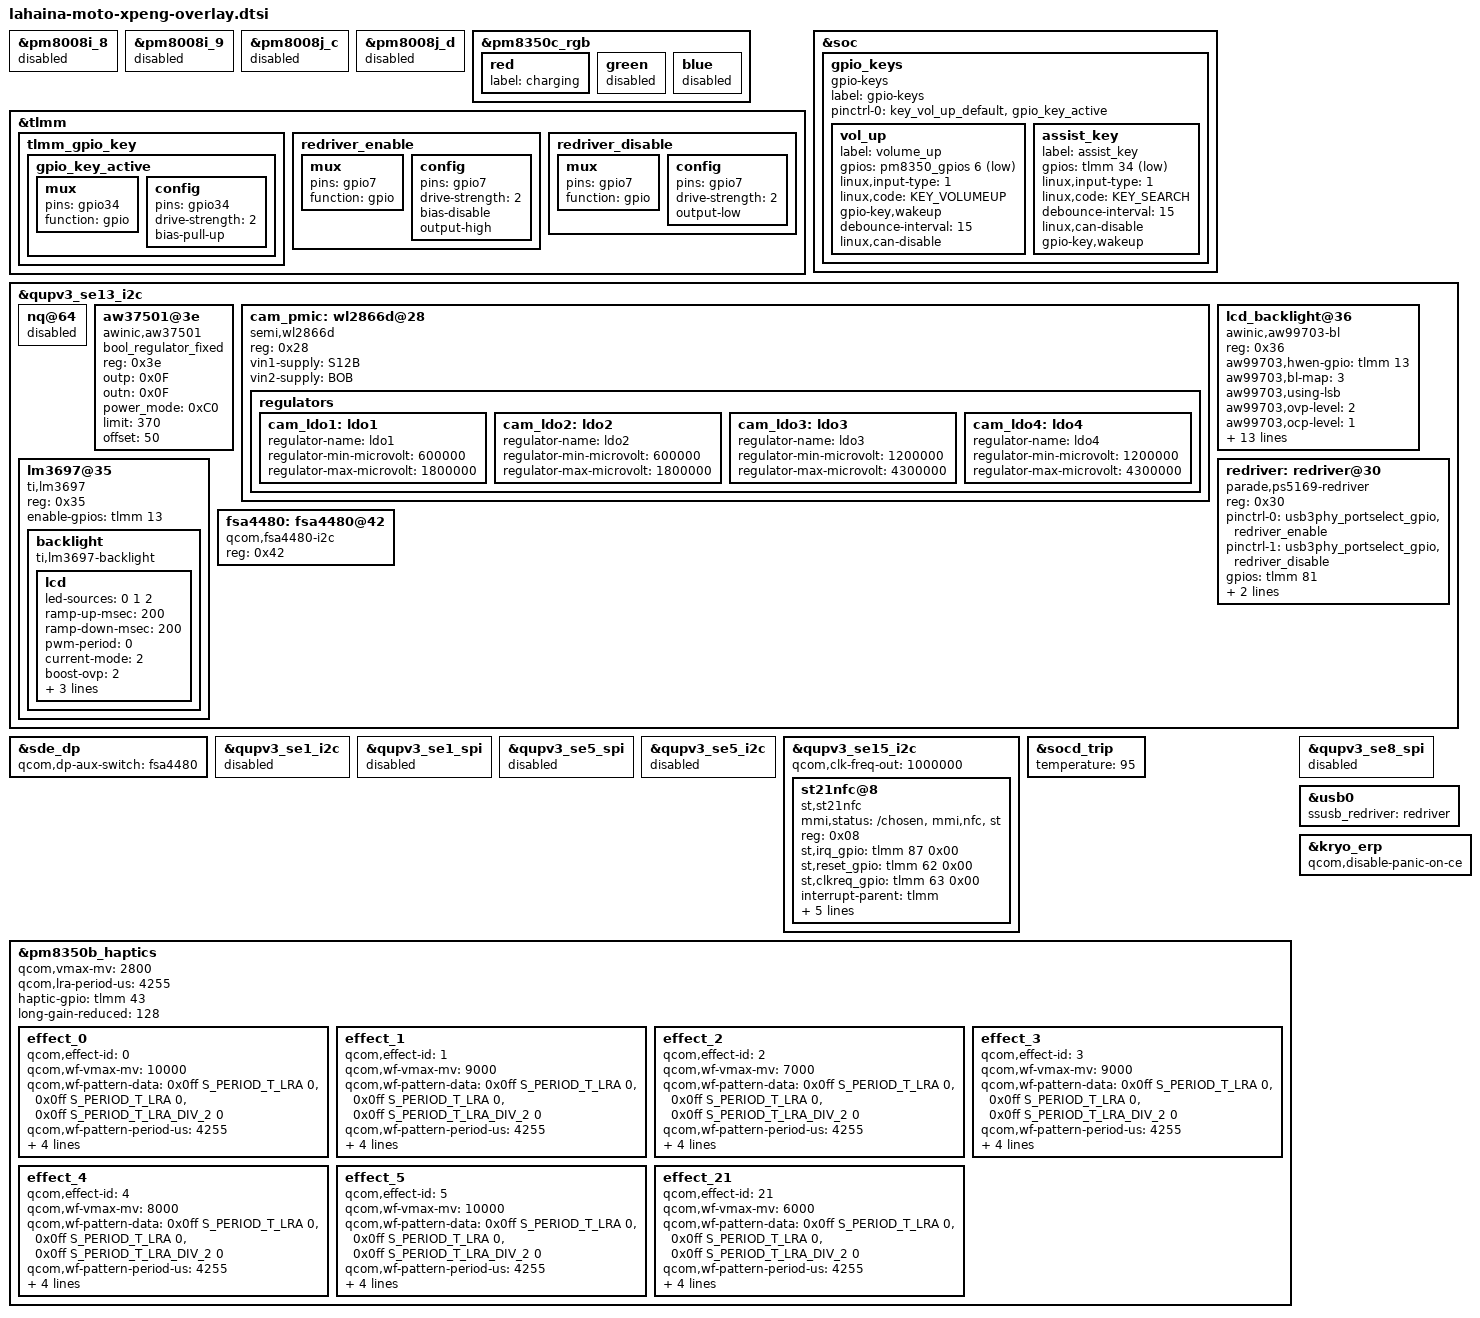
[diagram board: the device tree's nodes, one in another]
/* Copyright (c) 2020, The Linux Foundation. All rights reserved.
 *
 * This program is free software; you can redistribute it and/or modify
 * it under the terms of the GNU General Public License version 2 and
 * only version 2 as published by the Free Software Foundation.
 *
 * This program is distributed in the hope that it will be useful,
 * but WITHOUT ANY WARRANTY; without even the implied warranty of
 * MERCHANTABILITY or FITNESS FOR A PARTICULAR PURPOSE.  See the
 * GNU General Public License for more details.
 */

#include "lahaina-moto-common-overlay.dtsi"
#include "lahaina-moto-xpeng-display.dtsi"
#include "lahaina-dubai-vibrator.dtsi"
#include "lahaina-xpeng-touchscreen.dtsi"
#include <dt-bindings/clock/qcom,rpmh.h>
#include "lahaina-moto-common-charger.dtsi"
#include "lahaina-xpeng-audio-overlay.dtsi"
#include "lahaina-moto-xpeng-fps.dtsi"
#include "lahaina-xpeng-charger-therm-overlay.dtsi"
#include "lahaina-xpeng-sensor-overlay.dtsi"
#include "camera/lahaina-camera-sensor-mot-xpeng-overlay.dtsi"

&pm8008i_8 {
	status = "disabled";
};

&pm8008i_9 {
	status = "disabled";
};

&pm8008j_c {
	status = "disabled";
};

&pm8008j_d {
	status = "disabled";
};

&pm8350c_rgb {
	red {
		label = "charging";
	};
	green {
		status = "disabled";
	};
	blue {
		status = "disabled";
	};
};

&tlmm{
	tlmm_gpio_key {
		gpio_key_active: gpio_key_active {
			mux {
				pins = "gpio34";
				function = "gpio";
			};

			config {
				pins = "gpio34";
				drive-strength = <2>;
				bias-pull-up;
			};
		};
	};
};

&soc {
	gpio_keys {
		compatible = "gpio-keys";
		label = "gpio-keys";

		pinctrl-names = "default";
		pinctrl-0 = <&key_vol_up_default &gpio_key_active>;

		vol_up {
			label = "volume_up";
			gpios = <&pm8350_gpios 6 GPIO_ACTIVE_LOW>;
			linux,input-type = <1>;
			linux,code = <KEY_VOLUMEUP>;
			gpio-key,wakeup;
			debounce-interval = <15>;
			linux,can-disable;
		};

		assist_key{
			label = "assist_key";
			gpios = <&tlmm 34 0x1>;
			linux,input-type = <1>;
			linux,code = <KEY_SEARCH>;
			debounce-interval = <15>;
			linux,can-disable;
			gpio-key,wakeup;
		};
	};
};

&qupv3_se13_i2c {
	status = "ok";
	nq@64 {
		status = "disabled";
	};

	aw37501@3e {
		status = "okay";
		compatible = "awinic,aw37501";

		bool_regulator_fixed; /* use gpio regulator-fixed  */
		reg = <0x3e>;
		outp = <0x0F>;
		outn = <0x0F>;
		power_mode = <0xC0>;
		limit = <370>;
		offset = <50>;
	};

	cam_pmic: wl2866d@28{
		compatible = "semi,wl2866d";
		reg = <0x28>;

		vin1-supply = <&S12B>;
		vin2-supply = <&BOB>;

		regulators {
			cam_ldo1: ldo1 {
				regulator-name = "ldo1";
				regulator-min-microvolt = <600000>;
				regulator-max-microvolt = <1800000>;
			};

			cam_ldo2: ldo2 {
				regulator-name = "ldo2";
				regulator-min-microvolt = <600000>;
				regulator-max-microvolt = <1800000>;
			};

			cam_ldo3: ldo3 {
				regulator-name = "ldo3";
				regulator-min-microvolt = <1200000>;
				regulator-max-microvolt = <4300000>;
			};

			cam_ldo4: ldo4 {
				regulator-name = "ldo4";
				regulator-min-microvolt = <1200000>;
				regulator-max-microvolt = <4300000>;
			};
		};
	};

        lcd_backlight@36 {
                compatible = "awinic,aw99703-bl";
                reg = <0x36>;

		/* Awinic, aw99703 */
                aw99703,hwen-gpio = <&tlmm 13 0>;
                aw99703,bl-map = <3>; /* brightness map level 1:256,2:1024,3:2048 */
                aw99703,using-lsb;
                aw99703,ovp-level = <2>; /* 0:17.5V, 1:24V, 2:31V, 3:38V, 4:41.5V */
                aw99703,ocp-level = <1>; /* 0:0.9A, 1:1.8A, 2:2.7A, 3:3.4A */
                aw99703,switch-freq = <1>; /* 1000kHz(default) */
                aw99703,auto-freq-high = <0x10>;
                aw99703,auto-freq-low = <0x05>;
                aw99703,bl-fscal-led = <0x19>; /* 24.8mA */
                aw99703,bl-channel = <3>;
                aw99703,turn-on-ramp = <0x00>; /* 512us */
                aw99703,turn-off-ramp = <0x04>; /* 8ms */
                aw99703,pwm-trans-dim = <0>; /* 2ms */
                aw99703,i2c-trans-dim = <1>; /* 128ms */
                aw99703,pwm-mode = <1>; /* 1 pwm enable,0 PWM disable */
                aw99703,map-type = <4>; /* 0 exponential, 4 linear */
                aw99703,work-mode = <1>; /* backlight */
		aw99703,default-brightness = <1024>;

	};


        lm3697@35 {
                compatible = "ti,lm3697";
                reg = <0x35>;

		/* TI, lm3697*/
		enable-gpios = <&tlmm 13 0>;
		backlight {
			compatible = "ti,lm3697-backlight";
			lcd {
				led-sources = <0 1 2>;
				ramp-up-msec = <200>;
				ramp-down-msec = <200>;
				pwm-period = <0>;
				current-mode = <2>;	/*2: 25mA*/
				boost-ovp = <2>;	/*0:16v 1:24v 2:32v 3:40v*/
				boost-freq = <1>;	/*0:500Khz 1:1Mhz*/
				map-type = <1>;         /* 0 exponential, 1 linear */
				default-brightness-level = <1024>;
			};
		};
	};

	redriver:redriver@30{
		compatible = "parade,ps5169-redriver";
		reg = <0x30>;
		pinctrl-names = "enable_gpio", "disable_gpio";
		pinctrl-0 = <&usb3phy_portselect_gpio &redriver_enable>;
		pinctrl-1 = <&usb3phy_portselect_gpio &redriver_disable>;
		gpios = <&tlmm 81 0>;
		config-seq =
		        /* <reg_offset, value, delay_us> */
		        <0x9d 0x80 10000
		        0x9d 0x00 0
		        0x40 0x80 0
		        0x9f 0x02 0
		        0x8d 0x01 0
		        0x90 0x01 0
		        0x51 0x87 0
		        0x50 0x20 0
		        0x54 0x11 0
		        0x5d 0x66 0
		        0x52 0x50 0
		        0x55 0x00 0
		        0x56 0x00 0
		        0x57 0x00 0
		        0x58 0x00 0
		        0x59 0x00 0
		        0x5a 0x00 0
		        0x5b 0x00 0
		        0x5e 0x07 0
		        0x5f 0x00 0
		        0x60 0x00 0
		        0x61 0x03 0
		        0x65 0x40 0
		        0x66 0x00 0
		        0x67 0x03 0
		        0x75 0x0c 0
		        0x77 0x00 0
		        0x78 0x7c 0
		        >;
	};

        fsa4480: fsa4480@42 {
                compatible = "qcom,fsa4480-i2c";
                reg = <0x42>;
	};
};

&sde_dp {
        qcom,dp-aux-switch = <&fsa4480>;
};

&tlmm {
	redriver_enable: redriver_enable {
		mux {
			pins = "gpio7";
			function = "gpio";
		};

		config {
			pins = "gpio7";
			drive-strength = <2>;
			bias-disable; /* NO PULL */
			output-high;
		};
	};
	redriver_disable: redriver_disable {
		mux {
			pins = "gpio7";
				function = "gpio";
			};

		config {
			pins = "gpio7";
			drive-strength = <2>;
			output-low;
		};
	};

};

&qupv3_se1_i2c {
	status = "disabled";
};

&qupv3_se1_spi {
	status = "disabled";
};

&qupv3_se5_spi {
	status = "disabled";
};

&qupv3_se5_i2c {
	status = "disabled";
};

&qupv3_se15_i2c {
	status = "ok";
	qcom,clk-freq-out = <1000000>;
	#address-cells = <1>;
	#size-cells = <0>;
	st21nfc@8 {
		compatible = "st,st21nfc";
		mmi,status = "/chosen", "mmi,nfc", "st";
		status = "ok";
		reg = <0x08>;
		st,irq_gpio = <&tlmm 87 0x00>;
		st,reset_gpio = <&tlmm 62 0x00>;
		st,clkreq_gpio = <&tlmm 63 0x00>;
		interrupt-parent = <&tlmm>;
		interrupts = <87 0>;
		interrupt-names = "nfc_irq";
		pinctrl-names = "nfc_active", "nfc_suspend";
		pinctrl-0 = <&nfc_int_active &nfc_enable_active
				&nfc_clk_req_active>;
		pinctrl-1 = <&nfc_int_suspend &nfc_enable_suspend
				&nfc_clk_req_suspend>;
	};
};

&socd_trip {
	temperature = <95>;
};

&pm8350b_haptics {
	qcom,vmax-mv = <2800>;
	qcom,lra-period-us = <4255>;
	haptic-gpio = <&tlmm 43 0x00>;
	long-gain-reduced = <128>;
	status = "ok";

	effect_0 {
		/* CLICK */
		qcom,effect-id = <0>;
		qcom,wf-vmax-mv = <10000>;
		qcom,wf-pattern-data =  <0x0ff  S_PERIOD_T_LRA  0>,
					<0x0ff  S_PERIOD_T_LRA  0>,
					<0x0ff  S_PERIOD_T_LRA_DIV_2 0>;
		qcom,wf-pattern-period-us = <4255>;
		qcom,wf-brake-mode = <BRAKE_OPEN_LOOP>;
		qcom,wf-brake-pattern = /bits/ 8 <0xff 0xff 0x9f 0x6f 0x3f 0x1f>;
		qcom,wf-auto-res-disable;
	};

	effect_1 {
		/* DOUBLE_CLICK */
		qcom,effect-id = <1>;
		qcom,wf-vmax-mv = <9000>;
		qcom,wf-pattern-data =  <0x0ff  S_PERIOD_T_LRA  0>,
					<0x0ff  S_PERIOD_T_LRA  0>,
					<0x0ff  S_PERIOD_T_LRA_DIV_2 0>;
		qcom,wf-pattern-period-us = <4255>;
		qcom,wf-brake-mode = <BRAKE_OPEN_LOOP>;
		qcom,wf-brake-pattern = /bits/ 8 <0xff 0xff 0x9f 0x6f 0x3f 0x1f>;
		qcom,wf-auto-res-disable;
	};

	effect_2 {
		/* TICK */
		qcom,effect-id = <2>;
		qcom,wf-vmax-mv = <7000>;
		qcom,wf-pattern-data =  <0x0ff  S_PERIOD_T_LRA  0>,
					<0x0ff  S_PERIOD_T_LRA  0>,
					<0x0ff  S_PERIOD_T_LRA_DIV_2 0>;
		qcom,wf-pattern-period-us = <4255>;
		qcom,wf-brake-mode = <BRAKE_OPEN_LOOP>;
		qcom,wf-brake-pattern = /bits/ 8 <0xff 0xff 0x9f 0x6f 0x3f 0x1f>;
		qcom,wf-auto-res-disable;
	};

	effect_3 {
		/* THUD */
		qcom,effect-id = <3>;
		qcom,wf-vmax-mv = <9000>;
		qcom,wf-pattern-data =  <0x0ff  S_PERIOD_T_LRA  0>,
					<0x0ff  S_PERIOD_T_LRA  0>,
					<0x0ff  S_PERIOD_T_LRA_DIV_2 0>;
		qcom,wf-pattern-period-us = <4255>;
		qcom,wf-brake-mode = <BRAKE_OPEN_LOOP>;
		qcom,wf-brake-pattern = /bits/ 8 <0xff 0xff 0x9f 0x6f 0x3f 0x1f>;
		qcom,wf-auto-res-disable;
	};

	effect_4 {
		/* POP */
		qcom,effect-id = <4>;
		qcom,wf-vmax-mv = <8000>;
		qcom,wf-pattern-data =  <0x0ff  S_PERIOD_T_LRA  0>,
					<0x0ff  S_PERIOD_T_LRA  0>,
					<0x0ff  S_PERIOD_T_LRA_DIV_2 0>;
		qcom,wf-pattern-period-us = <4255>;
		qcom,wf-brake-mode = <BRAKE_OPEN_LOOP>;
		qcom,wf-brake-pattern = /bits/ 8 <0xff 0xff 0x9f 0x6f 0x3f 0x1f>;
		qcom,wf-auto-res-disable;
	};

	effect_5 {
		/* HEAVY CLICK */
		qcom,effect-id = <5>;
		qcom,wf-vmax-mv = <10000>;
		qcom,wf-pattern-data =  <0x0ff  S_PERIOD_T_LRA  0>,
					<0x0ff  S_PERIOD_T_LRA  0>,
					<0x0ff  S_PERIOD_T_LRA_DIV_2 0>;
		qcom,wf-pattern-period-us = <4255>;
		qcom,wf-brake-mode = <BRAKE_OPEN_LOOP>;
		qcom,wf-brake-pattern = /bits/ 8 <0xff 0xff 0x9f 0x6f 0x3f 0x1f>;
		qcom,wf-auto-res-disable;
	};

	effect_21 {
		/* TEXTURE_TICK */
		qcom,effect-id = <21>;
		qcom,wf-vmax-mv = <6000>;
		qcom,wf-pattern-data =  <0x0ff  S_PERIOD_T_LRA  0>,
					<0x0ff  S_PERIOD_T_LRA  0>,
					<0x0ff  S_PERIOD_T_LRA_DIV_2 0>;
		qcom,wf-pattern-period-us = <4255>;
		qcom,wf-brake-mode = <BRAKE_OPEN_LOOP>;
		qcom,wf-brake-pattern = /bits/ 8 <0xff 0xff 0x9f 0x6f 0x3f 0x1f>;
		qcom,wf-auto-res-disable;
	};
};

&qupv3_se8_spi {
	status = "disabled";
};

&usb0 {
	ssusb_redriver = <&redriver>;
};

&kryo_erp {
	qcom,disable-panic-on-ce;
};
